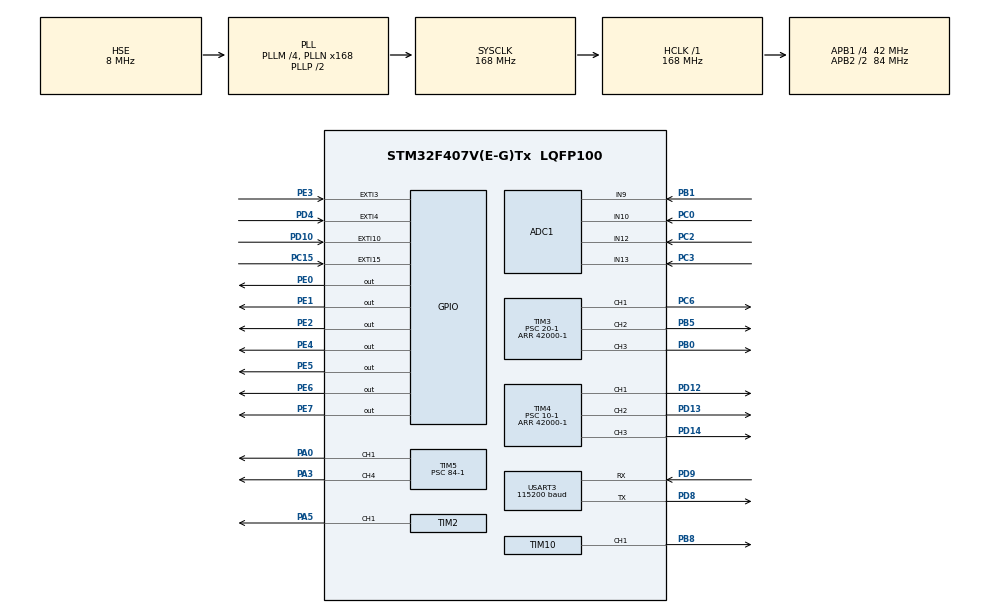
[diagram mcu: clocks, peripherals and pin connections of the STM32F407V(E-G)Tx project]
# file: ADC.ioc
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ADC1.Channel-0\#ChannelRegularConversion=ADC_CHANNEL_10
ADC1.Channel-1\#ChannelRegularConversion=ADC_CHANNEL_12
ADC1.Channel-2\#ChannelRegularConversion=ADC_CHANNEL_13
ADC1.Channel-3\#ChannelRegularConversion=ADC_CHANNEL_9
ADC1.ClockPrescaler=ADC_CLOCK_SYNC_PCLK_DIV4
ADC1.ContinuousConvMode=ENABLE
ADC1.DMAContinuousRequests=ENABLE
ADC1.NbrOfConversion=4
ADC1.NbrOfConversionFlag=1
ADC1.Rank-0\#ChannelRegularConversion=1
ADC1.Rank-1\#ChannelRegularConversion=2
ADC1.Rank-2\#ChannelRegularConversion=3
ADC1.Rank-3\#ChannelRegularConversion=4
ADC1.SamplingTime-0\#ChannelRegularConversion=ADC_SAMPLETIME_84CYCLES
ADC1.SamplingTime-1\#ChannelRegularConversion=ADC_SAMPLETIME_84CYCLES
ADC1.SamplingTime-2\#ChannelRegularConversion=ADC_SAMPLETIME_84CYCLES
ADC1.SamplingTime-3\#ChannelRegularConversion=ADC_SAMPLETIME_84CYCLES
ADC1.ScanConvMode=ENABLE
ADC1.master=1
Dma.ADC1.0.Direction=DMA_PERIPH_TO_MEMORY
Dma.ADC1.0.FIFOMode=DMA_FIFOMODE_DISABLE
Dma.ADC1.0.Instance=DMA2_Stream0
Dma.ADC1.0.MemDataAlignment=DMA_MDATAALIGN_HALFWORD
Dma.ADC1.0.MemInc=DMA_MINC_ENABLE
Dma.ADC1.0.Mode=DMA_CIRCULAR
Dma.ADC1.0.PeriphDataAlignment=DMA_PDATAALIGN_HALFWORD
Dma.ADC1.0.PeriphInc=DMA_PINC_DISABLE
Dma.ADC1.0.Priority=DMA_PRIORITY_LOW
Dma.Request0=ADC1
Mcu.Family=STM32F4
Mcu.Name=STM32F407V(E-G)Tx
Mcu.Package=LQFP100
NVIC.DMA2_Stream0_IRQn=true\:0\:0\:false\:false\:true\:false\:true
NVIC.EXTI15_10_IRQn=true\:0\:0\:false\:false\:true\:true\:true
NVIC.EXTI3_IRQn=true\:0\:0\:false\:false\:true\:true\:true
NVIC.EXTI4_IRQn=true\:0\:0\:false\:false\:true\:true\:true
NVIC.PriorityGroup=NVIC_PRIORITYGROUP_4
NVIC.TIM7_IRQn=true\:0\:0\:false\:false\:true\:true\:true
NVIC.USART3_IRQn=true\:0\:0\:false\:false\:true\:true\:true
PA0-WKUP.Signal=S_TIM5_CH1
PA3.Signal=S_TIM5_CH4
PA5.Signal=S_TIM2_CH1_ETR
PB0.Signal=S_TIM3_CH3
PB1.Signal=ADCx_IN9
PB5.Signal=S_TIM3_CH2
PB8.Signal=S_TIM10_CH1
PC0.Signal=ADCx_IN10
PC15-OSC32_OUT.GPIO_ModeDefaultEXTI=GPIO_MODE_IT_RISING_FALLING
PC15-OSC32_OUT.Signal=GPXTI15
PC2.Signal=ADCx_IN12
PC3.Signal=ADCx_IN13
PC6.Signal=S_TIM3_CH1
PD10.GPIO_ModeDefaultEXTI=GPIO_MODE_IT_RISING_FALLING
PD10.Signal=GPXTI10
PD12.Signal=S_TIM4_CH1
PD13.Signal=S_TIM4_CH2
PD14.Signal=S_TIM4_CH3
PD4.GPIO_ModeDefaultEXTI=GPIO_MODE_IT_RISING_FALLING
PD4.Signal=GPXTI4
PD8.Mode=Asynchronous
PD8.Signal=USART3_TX
PD9.Mode=Asynchronous
PD9.Signal=USART3_RX
PE0.Signal=GPIO_Output
PE1.Signal=GPIO_Output
PE2.Signal=GPIO_Output
PE3.GPIO_ModeDefaultEXTI=GPIO_MODE_IT_RISING_FALLING
PE3.Signal=GPXTI3
PE4.Signal=GPIO_Output
PE5.Signal=GPIO_Output
PE6.Signal=GPIO_Output
PE7.Signal=GPIO_Output
PH0-OSC_IN.Mode=HSE-External-Oscillator
PH0-OSC_IN.Signal=RCC_OSC_IN
PH1-OSC_OUT.Mode=HSE-External-Oscillator
PH1-OSC_OUT.Signal=RCC_OSC_OUT
ProjectManager.HeapSize=0x200
ProjectManager.StackSize=0x400
ProjectManager.TargetToolchain=TrueSTUDIO
RCC.48MHZClocksFreq_Value=84000000
RCC.AHBFreq_Value=168000000
RCC.APB1CLKDivider=RCC_HCLK_DIV4
RCC.APB1Freq_Value=42000000
RCC.APB1TimFreq_Value=84000000
RCC.APB2CLKDivider=RCC_HCLK_DIV2
RCC.APB2Freq_Value=84000000
RCC.APB2TimFreq_Value=168000000
RCC.CortexFreq_Value=168000000
RCC.HCLKFreq_Value=168000000
RCC.HSE_VALUE=8000000
RCC.HSI_VALUE=16000000
RCC.LSE_VALUE=32768
RCC.PLLM=4
RCC.PLLN=168
RCC.PLLSourceVirtual=RCC_PLLSOURCE_HSE
RCC.SYSCLKFreq_VALUE=168000000
RCC.SYSCLKSource=RCC_SYSCLKSOURCE_PLLCLK
RCC.VCOOutputFreq_Value=336000000
SH.ADCx_IN10.0=ADC1_IN10,IN10
SH.ADCx_IN12.0=ADC1_IN12,IN12
SH.ADCx_IN13.0=ADC1_IN13,IN13
SH.ADCx_IN9.0=ADC1_IN9,IN9
SH.S_TIM10_CH1.0=TIM10_CH1,PWM Generation1 CH1
SH.S_TIM2_CH1_ETR.0=TIM2_CH1,PWM Generation1 CH1
SH.S_TIM3_CH1.0=TIM3_CH1,PWM Generation1 CH1
SH.S_TIM3_CH2.0=TIM3_CH2,PWM Generation2 CH2
SH.S_TIM3_CH3.0=TIM3_CH3,PWM Generation3 CH3
SH.S_TIM4_CH1.0=TIM4_CH1,PWM Generation1 CH1
SH.S_TIM4_CH2.0=TIM4_CH2,PWM Generation2 CH2
SH.S_TIM4_CH3.0=TIM4_CH3,PWM Generation3 CH3
SH.S_TIM5_CH1.0=TIM5_CH1,PWM Generation1 CH1
SH.S_TIM5_CH4.0=TIM5_CH4,PWM Generation4 CH4
TIM10.Channel=TIM_CHANNEL_1
TIM10.Period=10000-1
TIM10.Prescaler=336-1
TIM10.Pulse=100
TIM2.AutoReloadPreload=TIM_AUTORELOAD_PRELOAD_DISABLE
TIM2.Channel-PWM\ Generation1\ CH1=TIM_CHANNEL_1
TIM2.Period=1000-1
TIM2.Prescaler=168-1
TIM2.Pulse-PWM\ Generation1\ CH1=500
TIM3.Channel-PWM\ Generation1\ CH1=TIM_CHANNEL_1
TIM3.Channel-PWM\ Generation2\ CH2=TIM_CHANNEL_2
TIM3.Channel-PWM\ Generation3\ CH3=TIM_CHANNEL_3
TIM3.Period=42000-1
TIM3.Prescaler=20-1
TIM3.Pulse-PWM\ Generation1\ CH1=21000-1
TIM3.Pulse-PWM\ Generation2\ CH2=15000-1
TIM3.Pulse-PWM\ Generation3\ CH3=5250-1
TIM4.Channel-PWM\ Generation1\ CH1=TIM_CHANNEL_1
TIM4.Channel-PWM\ Generation2\ CH2=TIM_CHANNEL_2
TIM4.Channel-PWM\ Generation3\ CH3=TIM_CHANNEL_3
TIM4.Period=42000-1
TIM4.Prescaler=10-1
TIM4.Pulse-PWM\ Generation1\ CH1=21000-1
TIM4.Pulse-PWM\ Generation2\ CH2=10500-1
TIM4.Pulse-PWM\ Generation3\ CH3=5250-1
TIM5.Channel-PWM\ Generation1\ CH1=TIM_CHANNEL_1
TIM5.Channel-PWM\ Generation4\ CH4=TIM_CHANNEL_4
TIM5.Period=10000-1
TIM5.Prescaler=84-1
TIM5.Pulse-PWM\ Generation1\ CH1=5000
TIM7.AutoReloadPreload=TIM_AUTORELOAD_PRELOAD_ENABLE
TIM7.Period=8399
TIM7.Prescaler=9999
USART3.BaudRate=115200
USART3.VirtualMode=VM_ASYNC
VP_TIM10_VS_ClockSourceINT.Mode=Enable_Timer
VP_TIM2_VS_ClockSourceINT.Mode=Internal
VP_TIM3_VS_ClockSourceINT.Mode=Internal
VP_TIM4_VS_ClockSourceINT.Mode=Internal
VP_TIM5_VS_ClockSourceINT.Mode=Internal
VP_TIM7_VS_ClockSourceINT.Mode=Enable_Timer
board=custom

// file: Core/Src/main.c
/* USER CODE BEGIN Header */
/**
  ******************************************************************************
  * @file           : main.c
  * @brief          : Main program body
  ******************************************************************************
  * @attention
  *
  * <h2><center>&copy; Copyright (c) 2020 STMicroelectronics.
  * All rights reserved.</center></h2>
  *
  * This software component is licensed by ST under BSD 3-Clause license,
  * the "License"; You may not use this file except in compliance with the
  * License. You may obtain a copy of the License at:
  *                        opensource.org/licenses/BSD-3-Clause
  *
  ******************************************************************************
  */
/* USER CODE END Header */
#include "main.h"
#include "adc.h"
#include "dma.h"
#include "tim.h"
#include "usart.h"
#include "gpio.h"

/* USER CODE BEGIN Includes */
#include	<stdio.h>
#include	"clcd.h"
/* USER CODE END Includes */

/* USER CODE BEGIN PD */
#define	ADC_SIZE	4
/* USER CODE END PD */

void SystemClock_Config(void);

int main(void)
{
  /* USER CODE BEGIN 1 */
  volatile uint16_t	adc_value[ADC_SIZE];
  /* USER CODE END 1 */

  /* MCU Configuration--------------------------------------------------------*/

  /* Reset of all peripherals, Initializes the Flash interface and the Systick. */
  HAL_Init();

  /* Configure the system clock */
  SystemClock_Config();

  /* Initialize all configured peripherals */
  MX_GPIO_Init();
  MX_DMA_Init();
  MX_USART3_UART_Init();
  MX_TIM7_Init();
  MX_TIM3_Init();
  MX_TIM4_Init();
  MX_TIM10_Init();
  MX_TIM2_Init();
  MX_TIM5_Init();
  MX_ADC1_Init();
  /* USER CODE BEGIN 2 */
  CLCD_GPIO_Init();
  CLCD_Init();
  CLCD_Clear();

  HAL_ADC_Start_DMA(&hadc1,&adc_value[0],ADC_SIZE);

  __HAL_TIM_SET_PRESCALER(&htim2,adc_value[0]);
  HAL_TIM_PWM_Start(&htim2, TIM_CHANNEL_1);

  /* USER CODE END 2 */

  /* Infinite loop */
  /* USER CODE BEGIN WHILE */
  uint8_t	str[CLCD_COL_SIZE];

  while (1)
  {
    /* USER CODE END WHILE */
	sprintf(str,"%04d  %04d",adc_value[0],adc_value[1]);
	CLCD_Puts(0,0,str);

	sprintf(str,"%04d  %04d",adc_value[2],adc_value[3]);
	CLCD_Puts(0,1,str);

	__HAL_TIM_SET_PRESCALER(&htim2,adc_value[0]);
	HAL_Delay(1);
  }
}

void SystemClock_Config(void)
{
  RCC_OscInitTypeDef RCC_OscInitStruct = {0};
  RCC_ClkInitTypeDef RCC_ClkInitStruct = {0};

  /** Configure the main internal regulator output voltage
  */
  __HAL_RCC_PWR_CLK_ENABLE();
  __HAL_PWR_VOLTAGESCALING_CONFIG(PWR_REGULATOR_VOLTAGE_SCALE1);
  /** Initializes the RCC Oscillators according to the specified parameters
  * in the RCC_OscInitTypeDef structure.
  */
  RCC_OscInitStruct.OscillatorType = RCC_OSCILLATORTYPE_HSE;
  RCC_OscInitStruct.HSEState = RCC_HSE_ON;
  RCC_OscInitStruct.PLL.PLLState = RCC_PLL_ON;
  RCC_OscInitStruct.PLL.PLLSource = RCC_PLLSOURCE_HSE;
  RCC_OscInitStruct.PLL.PLLM = 4;
  RCC_OscInitStruct.PLL.PLLN = 168;
  RCC_OscInitStruct.PLL.PLLP = RCC_PLLP_DIV2;
  RCC_OscInitStruct.PLL.PLLQ = 4;
  if (HAL_RCC_OscConfig(&RCC_OscInitStruct) != HAL_OK)
  {
    Error_Handler();
  }
  /** Initializes the CPU, AHB and APB buses clocks
  */
  RCC_ClkInitStruct.ClockType = RCC_CLOCKTYPE_HCLK|RCC_CLOCKTYPE_SYSCLK
                              |RCC_CLOCKTYPE_PCLK1|RCC_CLOCKTYPE_PCLK2;
  RCC_ClkInitStruct.SYSCLKSource = RCC_SYSCLKSOURCE_PLLCLK;
  RCC_ClkInitStruct.AHBCLKDivider = RCC_SYSCLK_DIV1;
  RCC_ClkInitStruct.APB1CLKDivider = RCC_HCLK_DIV4;
  RCC_ClkInitStruct.APB2CLKDivider = RCC_HCLK_DIV2;

  if (HAL_RCC_ClockConfig(&RCC_ClkInitStruct, FLASH_LATENCY_5) != HAL_OK)
  {
    Error_Handler();
  }
}

void Error_Handler(void)
{
}

/************************ (C) COPYRIGHT STMicroelectronics *****END OF FILE****/
